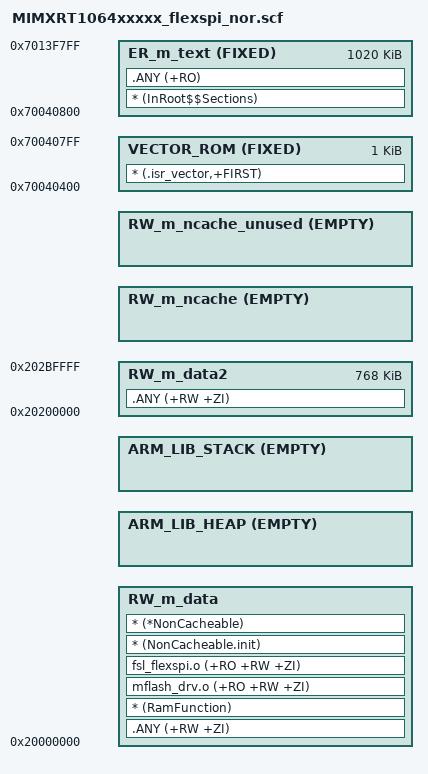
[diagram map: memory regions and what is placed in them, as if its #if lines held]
#!armclang --target=arm-arm-none-eabi -mcpu=cortex-m7 -E -x c
/*
** ###################################################################
**     Processors:          MIMXRT1064CVJ5A
**                          MIMXRT1064CVL5A
**                          MIMXRT1064DVJ6A
**                          MIMXRT1064DVL6A
**
**     Compiler:            Keil ARM C/C++ Compiler
**     Reference manual:    IMXRT1064RM Rev.0.1, 12/2018 | IMXRT1064SRM Rev.3
**     Version:             rev. 0.1, 2018-06-22
**     Build:               b190917
**
**     Abstract:
**         Linker file for the Keil ARM C/C++ Compiler
**
**     Copyright 2016 Freescale Semiconductor, Inc.
**     Copyright 2016-2019 NXP
**     All rights reserved.
**
**     SPDX-License-Identifier: BSD-3-Clause
**
**     http:                 www.nxp.com
**     mail:                 support@nxp.com
**
** ###################################################################
*/

#define m_interrupts_start             0x70040400
#define m_interrupts_size              0x00000400

/* NOTE: Flash in range 0x7013_EFFF - 0x7014_0000 is reserved for image trailer */

#define m_text_start                   0x70040800
#define m_text_size                    0x000FF000

#define m_data_start                   0x20000000
#define m_data_size                    0x00020000

#define m_data2_start                  0x20200000
#define m_data2_size                   0x000C0000

/* Sizes */
#if (defined(__stack_size__))
  #define Stack_Size                   __stack_size__
#else
  #define Stack_Size                   0x0400
#endif

#if (defined(__heap_size__))
  #define Heap_Size                    __heap_size__
#else
  #define Heap_Size                    0x0400
#endif


LR_m_text m_interrupts_start m_text_start+m_text_size-m_interrupts_start {   ; load region size_region
  VECTOR_ROM m_interrupts_start FIXED m_interrupts_size { ; load address = execution address
    * (.isr_vector,+FIRST)
  }
  ER_m_text m_text_start FIXED m_text_size { ; load address = execution address
    * (InRoot$$Sections)
    .ANY (+RO)
  }
  RW_m_data m_data_start m_data_size-Stack_Size-Heap_Size { ; RW data
    .ANY (+RW +ZI)
    * (RamFunction)
    /* Necessary to run flash routines from SRAM */
    mflash_drv.o (+RO +RW +ZI)
    fsl_flexspi.o (+RO +RW +ZI)
    * (NonCacheable.init)
    * (*NonCacheable)
  }
  ARM_LIB_HEAP +0 EMPTY Heap_Size {    ; Heap region growing up
  }
  ARM_LIB_STACK m_data_start+m_data_size EMPTY -Stack_Size { ; Stack region growing down
  }
  RW_m_data2 m_data2_start m_data2_size { ; RW data2
    .ANY (+RW +ZI)
  }
  RW_m_ncache +0 EMPTY 0 {
  }
  RW_m_ncache_unused +0 EMPTY m_data2_size-ImageLength(RW_m_data2)-ImageLength(RW_m_ncache) { ; Empty region added for MPU configuration
  }
}
